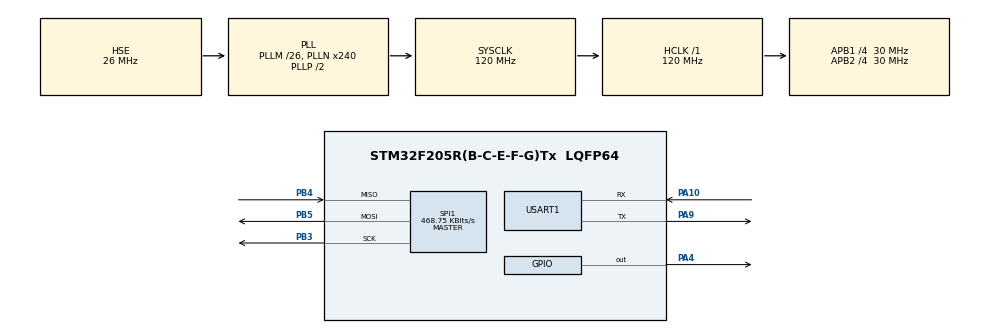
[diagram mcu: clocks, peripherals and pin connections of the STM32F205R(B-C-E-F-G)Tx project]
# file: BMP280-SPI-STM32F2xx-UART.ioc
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Mcu.Family=STM32F2
Mcu.Name=STM32F205R(B-C-E-F-G)Tx
Mcu.Package=LQFP64
NVIC.PriorityGroup=NVIC_PRIORITYGROUP_4
NVIC.TIM2_IRQn=true\:0\:0\:false\:false\:true\:true
NVIC.USART1_IRQn=true\:0\:0\:false\:false\:true\:true
PA10.GPIO_Speed=GPIO_SPEED_FREQ_VERY_HIGH
PA10.Mode=Asynchronous
PA10.Signal=USART1_RX
PA13.Mode=Serial_Wire
PA13.Signal=SYS_JTMS-SWDIO
PA14.Mode=Serial_Wire
PA14.Signal=SYS_JTCK-SWCLK
PA4.Signal=GPIO_Output
PA9.Mode=Asynchronous
PA9.Signal=USART1_TX
PB3.Mode=Full_Duplex_Master
PB3.Signal=SPI1_SCK
PB4.Mode=Full_Duplex_Master
PB4.Signal=SPI1_MISO
PB5.Mode=Full_Duplex_Master
PB5.Signal=SPI1_MOSI
PH0-OSC_IN.Mode=HSE-External-Oscillator
PH0-OSC_IN.Signal=RCC_OSC_IN
PH1-OSC_OUT.Mode=HSE-External-Oscillator
PH1-OSC_OUT.Signal=RCC_OSC_OUT
ProjectManager.HeapSize=0x200
ProjectManager.StackSize=0x400
ProjectManager.TargetToolchain=MDK-ARM V5
RCC.48MHZClocksFreq_Value=60000000
RCC.AHBFreq_Value=120000000
RCC.APB1CLKDivider=RCC_HCLK_DIV4
RCC.APB1Freq_Value=30000000
RCC.APB1TimFreq_Value=60000000
RCC.APB2CLKDivider=RCC_HCLK_DIV4
RCC.APB2Freq_Value=30000000
RCC.APB2TimFreq_Value=60000000
RCC.CortexFreq_Value=120000000
RCC.HCLKFreq_Value=120000000
RCC.HSE_VALUE=26000000
RCC.HSI_VALUE=16000000
RCC.LSE_VALUE=32768
RCC.PLLM=26
RCC.PLLN=240
RCC.PLLSourceVirtual=RCC_PLLSOURCE_HSE
RCC.SYSCLKFreq_VALUE=120000000
RCC.SYSCLKSource=RCC_SYSCLKSOURCE_PLLCLK
RCC.VCOOutputFreq_Value=240000000
SPI1.BaudRatePrescaler=SPI_BAUDRATEPRESCALER_64
SPI1.CalculateBaudRate=468.75 KBits/s
SPI1.Direction=SPI_DIRECTION_2LINES
SPI1.Mode=SPI_MODE_MASTER
SPI1.VirtualType=VM_MASTER
TIM2.Period=5001
TIM2.Prescaler=40000
TIM2.TIM_MasterOutputTrigger=TIM_TRGO_UPDATE
USART1.VirtualMode=VM_ASYNC
VP_TIM2_VS_ClockSourceINT.Mode=Internal
board=BMP280-SPI-STM32F2xx-UART

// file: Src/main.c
/**
  ******************************************************************************
  * @file           : main.c
  * @brief          : Main program body
  ******************************************************************************
  ** This notice applies to any and all portions of this file
  * that are not between comment pairs USER CODE BEGIN and
  * USER CODE END. Other portions of this file, whether
  * inserted by the user or by software development tools
  * are owned by their respective copyright owners.
  *
  * COPYRIGHT(c) 2018 STMicroelectronics
																																				 CEBRIАN
  ******************************************************************************
  */
#include "main.h"
#include "stm32f2xx_hal.h"

SPI_HandleTypeDef hspi1;

TIM_HandleTypeDef htim2;

UART_HandleTypeDef huart1;

/* USER CODE BEGIN PV */
/* Private variables ---------------------------------------------------------*/

/* USER CODE END PV */

void SystemClock_Config(void);
static void MX_GPIO_Init(void);
static void MX_USART1_UART_Init(void);
static void MX_TIM2_Init(void);
static void MX_SPI1_Init(void);

/* USER CODE BEGIN PFP */
/* Private function prototypes -----------------------------------------------*/
extern void UARTInterface(void);
/* USER CODE END PFP */

int main(void)
{

  /* MCU Configuration----------------------------------------------------------*/

  /* Reset of all peripherals, Initializes the Flash interface and the Systick. */
  HAL_Init();

  /* Configure the system clock */
  SystemClock_Config();

  /* Initialize all configured peripherals */
  MX_GPIO_Init();
  MX_USART1_UART_Init();
  MX_TIM2_Init();
  MX_SPI1_Init();
  /* USER CODE BEGIN 2 */
	UARTInterface();
  /* USER CODE END 2 */
	HAL_GPIO_WritePin(GPIOA, GPIO_PIN_4, GPIO_PIN_SET);
  /* Infinite loop */
  while (1)
  {

  }

}

void SystemClock_Config(void)
{

  RCC_OscInitTypeDef RCC_OscInitStruct;
  RCC_ClkInitTypeDef RCC_ClkInitStruct;

    /**Initializes the CPU, AHB and APB busses clocks
    */
  RCC_OscInitStruct.OscillatorType = RCC_OSCILLATORTYPE_HSE;
  RCC_OscInitStruct.HSEState = RCC_HSE_ON;
  RCC_OscInitStruct.PLL.PLLState = RCC_PLL_ON;
  RCC_OscInitStruct.PLL.PLLSource = RCC_PLLSOURCE_HSE;
  RCC_OscInitStruct.PLL.PLLM = 26;
  RCC_OscInitStruct.PLL.PLLN = 240;
  RCC_OscInitStruct.PLL.PLLP = RCC_PLLP_DIV2;
  RCC_OscInitStruct.PLL.PLLQ = 4;
  if (HAL_RCC_OscConfig(&RCC_OscInitStruct) != HAL_OK)
  {
    _Error_Handler(__FILE__, __LINE__);
  }

    /**Initializes the CPU, AHB and APB busses clocks
    */
  RCC_ClkInitStruct.ClockType = RCC_CLOCKTYPE_HCLK|RCC_CLOCKTYPE_SYSCLK
                              |RCC_CLOCKTYPE_PCLK1|RCC_CLOCKTYPE_PCLK2;
  RCC_ClkInitStruct.SYSCLKSource = RCC_SYSCLKSOURCE_PLLCLK;
  RCC_ClkInitStruct.AHBCLKDivider = RCC_SYSCLK_DIV1;
  RCC_ClkInitStruct.APB1CLKDivider = RCC_HCLK_DIV4;
  RCC_ClkInitStruct.APB2CLKDivider = RCC_HCLK_DIV4;

  if (HAL_RCC_ClockConfig(&RCC_ClkInitStruct, FLASH_LATENCY_3) != HAL_OK)
  {
    _Error_Handler(__FILE__, __LINE__);
  }

    /**Configure the Systick interrupt time
    */
  HAL_SYSTICK_Config(HAL_RCC_GetHCLKFreq()/1000);

    /**Configure the Systick
    */
  HAL_SYSTICK_CLKSourceConfig(SYSTICK_CLKSOURCE_HCLK);

  /* SysTick_IRQn interrupt configuration */
  HAL_NVIC_SetPriority(SysTick_IRQn, 0, 0);
}

/* SPI1 init function */
static void MX_SPI1_Init(void)
{

  /* SPI1 parameter configuration*/
  hspi1.Instance = SPI1;
  hspi1.Init.Mode = SPI_MODE_MASTER;
  hspi1.Init.Direction = SPI_DIRECTION_2LINES;
  hspi1.Init.DataSize = SPI_DATASIZE_8BIT;
  hspi1.Init.CLKPolarity = SPI_POLARITY_LOW;
  hspi1.Init.CLKPhase = SPI_PHASE_1EDGE;
  hspi1.Init.NSS = SPI_NSS_SOFT;
  hspi1.Init.BaudRatePrescaler = SPI_BAUDRATEPRESCALER_64;
  hspi1.Init.FirstBit = SPI_FIRSTBIT_MSB;
  hspi1.Init.TIMode = SPI_TIMODE_DISABLE;
  hspi1.Init.CRCCalculation = SPI_CRCCALCULATION_DISABLE;
  hspi1.Init.CRCPolynomial = 10;
  if (HAL_SPI_Init(&hspi1) != HAL_OK)
  {
    _Error_Handler(__FILE__, __LINE__);
  }

}

/* TIM2 init function */
static void MX_TIM2_Init(void)
{

  TIM_ClockConfigTypeDef sClockSourceConfig;
  TIM_MasterConfigTypeDef sMasterConfig;

  htim2.Instance = TIM2;
  htim2.Init.Prescaler = 60000;
  htim2.Init.CounterMode = TIM_COUNTERMODE_UP;
  htim2.Init.Period = 5001;
  htim2.Init.ClockDivision = TIM_CLOCKDIVISION_DIV1;
  htim2.Init.AutoReloadPreload = TIM_AUTORELOAD_PRELOAD_DISABLE;
  if (HAL_TIM_Base_Init(&htim2) != HAL_OK)
  {
    _Error_Handler(__FILE__, __LINE__);
  }

  sClockSourceConfig.ClockSource = TIM_CLOCKSOURCE_INTERNAL;
  if (HAL_TIM_ConfigClockSource(&htim2, &sClockSourceConfig) != HAL_OK)
  {
    _Error_Handler(__FILE__, __LINE__);
  }

  sMasterConfig.MasterOutputTrigger = TIM_TRGO_UPDATE;
  sMasterConfig.MasterSlaveMode = TIM_MASTERSLAVEMODE_DISABLE;
  if (HAL_TIMEx_MasterConfigSynchronization(&htim2, &sMasterConfig) != HAL_OK)
  {
    _Error_Handler(__FILE__, __LINE__);
  }

}

/* USART1 init function */
static void MX_USART1_UART_Init(void)
{

  huart1.Instance = USART1;
  huart1.Init.BaudRate = 115200;
  huart1.Init.WordLength = UART_WORDLENGTH_8B;
  huart1.Init.StopBits = UART_STOPBITS_1;
  huart1.Init.Parity = UART_PARITY_NONE;
  huart1.Init.Mode = UART_MODE_TX_RX;
  huart1.Init.HwFlowCtl = UART_HWCONTROL_NONE;
  huart1.Init.OverSampling = UART_OVERSAMPLING_16;
  if (HAL_UART_Init(&huart1) != HAL_OK)
  {
    _Error_Handler(__FILE__, __LINE__);
  }

}

/** Configure pins as
        * Analog
        * Input
        * Output
        * EVENT_OUT
        * EXTI
*/
static void MX_GPIO_Init(void)
{

  GPIO_InitTypeDef GPIO_InitStruct;

  /* GPIO Ports Clock Enable */
  __HAL_RCC_GPIOH_CLK_ENABLE();
  __HAL_RCC_GPIOA_CLK_ENABLE();
  __HAL_RCC_GPIOB_CLK_ENABLE();

  /*Configure GPIO pin Output Level */
  HAL_GPIO_WritePin(GPIOA, GPIO_PIN_4, GPIO_PIN_RESET);

  /*Configure GPIO pin : PA4 */
  GPIO_InitStruct.Pin = GPIO_PIN_4;
  GPIO_InitStruct.Mode = GPIO_MODE_OUTPUT_PP;
  GPIO_InitStruct.Pull = GPIO_NOPULL;
  GPIO_InitStruct.Speed = GPIO_SPEED_FREQ_LOW;
  HAL_GPIO_Init(GPIOA, &GPIO_InitStruct);

}

void _Error_Handler(char *file, int line)
{
  while(1)
  {
  }
}

/************************ (C) COPYRIGHT STMicroelectronics *****END OF FILE****/
